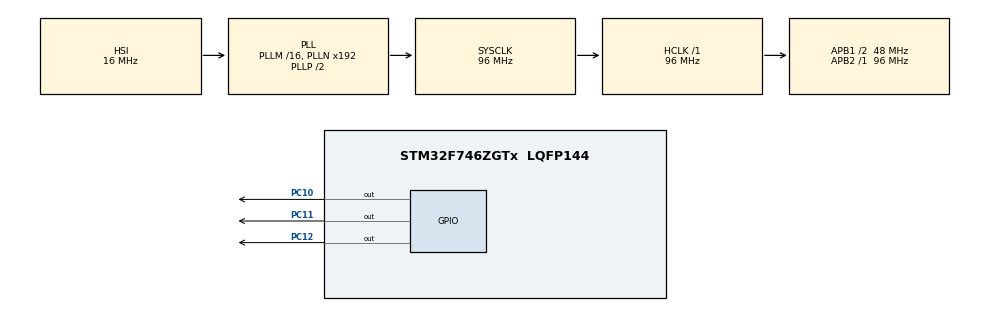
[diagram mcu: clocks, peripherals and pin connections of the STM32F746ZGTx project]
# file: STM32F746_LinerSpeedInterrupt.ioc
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Mcu.Family=STM32F7
RCC.CortexFreq_Value=96000000
PC12.Signal=GPIO_Output
PC11.Signal=GPIO_Output
PC10.Signal=GPIO_Output
TIM1.Channel-Output\ Compare1\ No\ Output=TIM_CHANNEL_1
RCC.APB1CLKDivider=RCC_HCLK_DIV2
RCC.SYSCLKSource=RCC_SYSCLKSOURCE_PLLCLK
ProjectManager.StackSize=0x400
VP_TIM1_VS_no_output1.Mode=Output Compare1 No Output
TIM1.Prescaler=16-1
ProjectManager.TargetToolchain=STM32CubeIDE
RCC.HCLKFreq_Value=96000000
RCC.APB2TimFreq_Value=96000000
RCC.USBFreq_Value=96000000
RCC.LSE_VALUE=32768
RCC.AHBFreq_Value=96000000
RCC.HSE_VALUE=25000000
board=custom
RCC.VCOOutputFreq_Value=192000000
RCC.APB2Freq_Value=96000000
Mcu.Name=STM32F746ZGTx
VP_TIM1_VS_ClockSourceINT.Mode=Internal
NVIC.TIM1_CC_IRQn=true\:0\:0\:false\:false\:true\:true\:true
RCC.SYSCLKFreq_VALUE=96000000
Mcu.Package=LQFP144
ProjectManager.HeapSize=0x200
RCC.HSI_VALUE=16000000
NVIC.PriorityGroup=NVIC_PRIORITYGROUP_4
RCC.APB1TimFreq_Value=96000000
RCC.APB1Freq_Value=48000000

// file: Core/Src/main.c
/* USER CODE BEGIN Header */
/**
  ******************************************************************************
  * @file           : main.c
  * @brief          : Main program body
  ******************************************************************************
  * @attention
  *
  * <h2><center>&copy; Copyright (c) 2021 STMicroelectronics.
  * All rights reserved.</center></h2>
  *
  * This software component is licensed by ST under BSD 3-Clause license,
  * the "License"; You may not use this file except in compliance with the
  * License. You may obtain a copy of the License at:
  *                        opensource.org/licenses/BSD-3-Clause
  *
  ******************************************************************************
  */
/* USER CODE END Header */
#include "main.h"

/* USER CODE BEGIN Includes */
#include <stdlib.h>
#include <math.h>
/* USER CODE END Includes */

/* USER CODE BEGIN PTD */
typedef struct {
	float acceleration;
	volatile unsigned int minStepInterval;
	void (*dirFunc)(int);
	void (*stepFunc)();

	unsigned int c0;
	long stepPosition;

	volatile int dir;
	volatile unsigned int totalSteps;
	volatile char movementDone;
	volatile unsigned int rampUpStepCount;

	volatile unsigned int n; // index
	volatile float d; // current interval length
	volatile unsigned long di; // d -> unsigned  di
	volatile unsigned int stepCount;
}stepperInfo;

/* USER CODE END PTD */

/* USER CODE BEGIN PD */
#define NUM_STEPPERS 1
/* USER CODE END PD */

TIM_HandleTypeDef htim1;

/* USER CODE BEGIN PV */
volatile stepperInfo steppers[NUM_STEPPERS];
/* USER CODE END PV */

void SystemClock_Config(void);
static void MX_GPIO_Init(void);
static void MX_TIM1_Init(void);

/* USER CODE BEGIN 0 */

void Step(){
	HAL_GPIO_WritePin(GPIOC, GPIO_PIN_12, GPIO_PIN_SET);
	HAL_GPIO_WritePin(GPIOC, GPIO_PIN_12, GPIO_PIN_RESET);
}

void Dir(int dir){
	HAL_GPIO_WritePin(GPIOC, GPIO_PIN_11, dir);
}

void resetStepperInfo(stepperInfo * si){
	si->n = 0;
	si->d = 0;
	si->di = 0;
	si->stepCount = 0;
	si->rampUpStepCount = 0;
	si->totalSteps = 0;
	si->stepPosition = 0;
	si->movementDone = 0;
}

void resetStepper(volatile stepperInfo* si){
	si->c0 = si->acceleration;
	si->d = si->c0;
	si->di = si->d;
	si->stepCount = 0;
	si->n = 0;
	si->rampUpStepCount = 0;
	si->movementDone = 0;
}

volatile uint8_t remainingSteppersFlag = 0;

void prepareMovement(int whichMotor, int steps){
	volatile stepperInfo* si = &steppers[whichMotor];
	si->dirFunc( steps < 0 ? 1 : 0);
	si->dir = steps > 0 ? 1:-1;
	si->totalSteps = abs(steps);
	resetStepper(si);
	remainingSteppersFlag |= (1 << whichMotor);
}

volatile uint8_t nextStepperFlag = 0;

void setNextInterruptInterval(){

	unsigned int mind = 999999;
	for (int i = 0; i < NUM_STEPPERS; i++){
		if( ((1 << i) & remainingSteppersFlag) && steppers[i].di < mind ){
			mind = steppers[i].di;
		}
	}

	nextStepperFlag = 0;
	for (int i = 0; i < NUM_STEPPERS; i ++){
		if( ((1 << i) & remainingSteppersFlag) && steppers[i].di == mind )
			nextStepperFlag |= (1 << i);
	}

	if (remainingSteppersFlag == 0){
		__HAL_TIM_SET_COMPARE(&htim1, TIM_CHANNEL_1, 65500);
	}

	__HAL_TIM_SET_COMPARE(&htim1, TIM_CHANNEL_1, mind);

}

void HAL_TIM_OC_DelayElapsedCallback(TIM_HandleTypeDef *htim){
	//HAL_TIM_OC_Stop_IT(&htim1, TIM_CHANNEL_1);
	unsigned int tmpCtr = __HAL_TIM_GET_COMPARE(&htim1, TIM_CHANNEL_1);
	__HAL_TIM_SET_COMPARE(&htim1, TIM_CHANNEL_1, 65500);

	for (int i = 0; i < NUM_STEPPERS; i++){
		if ( ! ( (1 << i) & remainingSteppersFlag )){
			continue;
		}
		if ( ! (nextStepperFlag & (1 << i)) ){
			steppers[i].di -= tmpCtr;
			continue;
		}

		volatile stepperInfo* s = &steppers[i];

		if( (s->stepCount) < (s->totalSteps) ){
			s->stepFunc();
			s->stepCount++;
			s->stepPosition += s->dir;
			if ( (s->stepCount) >= (s->totalSteps) ){
				s->movementDone = 1;
				remainingSteppersFlag &= ~(1 << i);
			}
		}

		if (s->rampUpStepCount == 0){
			s->n++;
			s->d = s->d - (2*s->d) / (4*s->n +1);
			if (s->d <= s->minStepInterval ){
				s->d = s->minStepInterval;
				s->rampUpStepCount = s->stepCount;
			}
			if (s->stepCount >= (s->totalSteps / 2) ){
				s->rampUpStepCount = s->stepCount;
			}
		} else if ( s->stepCount >= s->totalSteps - s->rampUpStepCount) {
			s->d = (s->d * (4 * s->n + 1)) / (4 * s->n + 1 -2);
			s->n--;
		}
	}

	setNextInterruptInterval();

	__HAL_TIM_SET_COUNTER(&htim1, 0);

}

void runAndWait(){
	setNextInterruptInterval();
	while(remainingSteppersFlag);
}

/* USER CODE END 0 */

int main(void)
{

  /* MCU Configuration--------------------------------------------------------*/

  /* Reset of all peripherals, Initializes the Flash interface and the Systick. */
  HAL_Init();

  /* Configure the system clock */
  SystemClock_Config();

  /* Initialize all configured peripherals */
  MX_GPIO_Init();
  MX_TIM1_Init();
  /* USER CODE BEGIN 2 */
  steppers[0].dirFunc = Dir;
  steppers[0].stepFunc = Step;
  steppers[0].acceleration = 5000;
  steppers[0].minStepInterval = 1;

  HAL_TIM_OC_Start_IT(&htim1, TIM_CHANNEL_1);
  /* USER CODE END 2 */

  /* Infinite loop */
  while (1)
  {

    /* USER CODE BEGIN 3 */
	  prepareMovement(0, 60000);
	  runAndWait();
	  HAL_Delay(100);
	  prepareMovement(0, -60000);
	  runAndWait();
	  HAL_Delay(1000);

  }
  /* USER CODE END 3 */
}

void SystemClock_Config(void)
{
  RCC_OscInitTypeDef RCC_OscInitStruct = {0};
  RCC_ClkInitTypeDef RCC_ClkInitStruct = {0};

  /** Configure the main internal regulator output voltage
  */
  __HAL_RCC_PWR_CLK_ENABLE();
  __HAL_PWR_VOLTAGESCALING_CONFIG(PWR_REGULATOR_VOLTAGE_SCALE3);
  /** Initializes the RCC Oscillators according to the specified parameters
  * in the RCC_OscInitTypeDef structure.
  */
  RCC_OscInitStruct.OscillatorType = RCC_OSCILLATORTYPE_HSI;
  RCC_OscInitStruct.HSIState = RCC_HSI_ON;
  RCC_OscInitStruct.HSICalibrationValue = RCC_HSICALIBRATION_DEFAULT;
  RCC_OscInitStruct.PLL.PLLState = RCC_PLL_ON;
  RCC_OscInitStruct.PLL.PLLSource = RCC_PLLSOURCE_HSI;
  RCC_OscInitStruct.PLL.PLLM = 16;
  RCC_OscInitStruct.PLL.PLLN = 192;
  RCC_OscInitStruct.PLL.PLLP = RCC_PLLP_DIV2;
  RCC_OscInitStruct.PLL.PLLQ = 2;
  if (HAL_RCC_OscConfig(&RCC_OscInitStruct) != HAL_OK)
  {
    Error_Handler();
  }
  /** Activate the Over-Drive mode
  */
  if (HAL_PWREx_EnableOverDrive() != HAL_OK)
  {
    Error_Handler();
  }
  /** Initializes the CPU, AHB and APB buses clocks
  */
  RCC_ClkInitStruct.ClockType = RCC_CLOCKTYPE_HCLK|RCC_CLOCKTYPE_SYSCLK
                              |RCC_CLOCKTYPE_PCLK1|RCC_CLOCKTYPE_PCLK2;
  RCC_ClkInitStruct.SYSCLKSource = RCC_SYSCLKSOURCE_PLLCLK;
  RCC_ClkInitStruct.AHBCLKDivider = RCC_SYSCLK_DIV1;
  RCC_ClkInitStruct.APB1CLKDivider = RCC_HCLK_DIV2;
  RCC_ClkInitStruct.APB2CLKDivider = RCC_HCLK_DIV1;

  if (HAL_RCC_ClockConfig(&RCC_ClkInitStruct, FLASH_LATENCY_3) != HAL_OK)
  {
    Error_Handler();
  }
}

static void MX_TIM1_Init(void)
{

  TIM_ClockConfigTypeDef sClockSourceConfig = {0};
  TIM_MasterConfigTypeDef sMasterConfig = {0};
  TIM_OC_InitTypeDef sConfigOC = {0};
  TIM_BreakDeadTimeConfigTypeDef sBreakDeadTimeConfig = {0};

  htim1.Instance = TIM1;
  htim1.Init.Prescaler = 8-1;
  htim1.Init.CounterMode = TIM_COUNTERMODE_UP;
  htim1.Init.Period = 65535;
  htim1.Init.ClockDivision = TIM_CLOCKDIVISION_DIV1;
  htim1.Init.RepetitionCounter = 0;
  htim1.Init.AutoReloadPreload = TIM_AUTORELOAD_PRELOAD_DISABLE;
  if (HAL_TIM_Base_Init(&htim1) != HAL_OK)
  {
    Error_Handler();
  }
  sClockSourceConfig.ClockSource = TIM_CLOCKSOURCE_INTERNAL;
  if (HAL_TIM_ConfigClockSource(&htim1, &sClockSourceConfig) != HAL_OK)
  {
    Error_Handler();
  }
  if (HAL_TIM_OC_Init(&htim1) != HAL_OK)
  {
    Error_Handler();
  }
  sMasterConfig.MasterOutputTrigger = TIM_TRGO_RESET;
  sMasterConfig.MasterOutputTrigger2 = TIM_TRGO2_RESET;
  sMasterConfig.MasterSlaveMode = TIM_MASTERSLAVEMODE_DISABLE;
  if (HAL_TIMEx_MasterConfigSynchronization(&htim1, &sMasterConfig) != HAL_OK)
  {
    Error_Handler();
  }
  sConfigOC.OCMode = TIM_OCMODE_TIMING;
  sConfigOC.Pulse = 1000;
  sConfigOC.OCPolarity = TIM_OCPOLARITY_HIGH;
  sConfigOC.OCNPolarity = TIM_OCNPOLARITY_HIGH;
  sConfigOC.OCFastMode = TIM_OCFAST_DISABLE;
  sConfigOC.OCIdleState = TIM_OCIDLESTATE_RESET;
  sConfigOC.OCNIdleState = TIM_OCNIDLESTATE_RESET;
  if (HAL_TIM_OC_ConfigChannel(&htim1, &sConfigOC, TIM_CHANNEL_1) != HAL_OK)
  {
    Error_Handler();
  }
  sBreakDeadTimeConfig.OffStateRunMode = TIM_OSSR_DISABLE;
  sBreakDeadTimeConfig.OffStateIDLEMode = TIM_OSSI_DISABLE;
  sBreakDeadTimeConfig.LockLevel = TIM_LOCKLEVEL_OFF;
  sBreakDeadTimeConfig.DeadTime = 0;
  sBreakDeadTimeConfig.BreakState = TIM_BREAK_DISABLE;
  sBreakDeadTimeConfig.BreakPolarity = TIM_BREAKPOLARITY_HIGH;
  sBreakDeadTimeConfig.BreakFilter = 0;
  sBreakDeadTimeConfig.Break2State = TIM_BREAK2_DISABLE;
  sBreakDeadTimeConfig.Break2Polarity = TIM_BREAK2POLARITY_HIGH;
  sBreakDeadTimeConfig.Break2Filter = 0;
  sBreakDeadTimeConfig.AutomaticOutput = TIM_AUTOMATICOUTPUT_DISABLE;
  if (HAL_TIMEx_ConfigBreakDeadTime(&htim1, &sBreakDeadTimeConfig) != HAL_OK)
  {
    Error_Handler();
  }

}

static void MX_GPIO_Init(void)
{
  GPIO_InitTypeDef GPIO_InitStruct = {0};

  /* GPIO Ports Clock Enable */
  __HAL_RCC_GPIOC_CLK_ENABLE();

  /*Configure GPIO pin Output Level */
  HAL_GPIO_WritePin(GPIOC, GPIO_PIN_10|GPIO_PIN_11|GPIO_PIN_12, GPIO_PIN_RESET);

  /*Configure GPIO pins : PC10 PC11 PC12 */
  GPIO_InitStruct.Pin = GPIO_PIN_10|GPIO_PIN_11|GPIO_PIN_12;
  GPIO_InitStruct.Mode = GPIO_MODE_OUTPUT_PP;
  GPIO_InitStruct.Pull = GPIO_NOPULL;
  GPIO_InitStruct.Speed = GPIO_SPEED_FREQ_LOW;
  HAL_GPIO_Init(GPIOC, &GPIO_InitStruct);

}

void Error_Handler(void)
{
  __disable_irq();
  while (1)
  {
  }
}

/************************ (C) COPYRIGHT STMicroelectronics *****END OF FILE****/
